# iostr730 register map
Registers are 16-bit, access not given, no defined reset value unless marked. A register's access mark holds for its fields unless they carry their own. Addresses are absolute; registers are grouped by the start of their names; [hi:lo] are bit positions; {n}, {i} and the like mark numbered series.

## GPIOPORT0
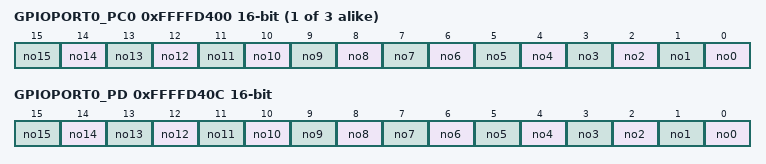
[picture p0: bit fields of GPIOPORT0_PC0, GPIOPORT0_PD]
{0xFFFFD400+4i} GPIOPORT0_PC{i} (i=0..2)
  [n] no{n} (n=0..15)
0xFFFFD40C GPIOPORT0_PD
  [n] no{n} (n=0..15)

## GPIOPORT1
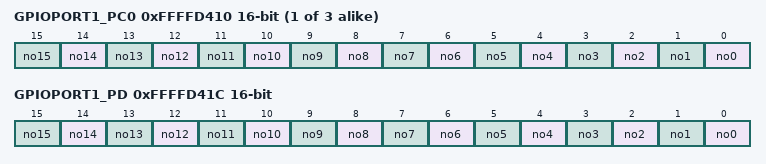
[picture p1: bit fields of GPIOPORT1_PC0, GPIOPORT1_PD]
{0xFFFFD410+4i} GPIOPORT1_PC{i} (i=0..2)
  [n] no{n} (n=0..15)
0xFFFFD41C GPIOPORT1_PD
  [n] no{n} (n=0..15)

## GPIOPORT2
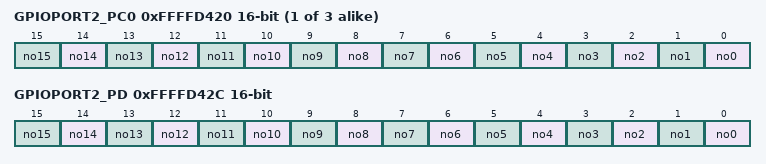
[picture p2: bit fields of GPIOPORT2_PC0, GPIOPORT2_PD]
{0xFFFFD420+4i} GPIOPORT2_PC{i} (i=0..2)
  [n] no{n} (n=0..15)
0xFFFFD42C GPIOPORT2_PD
  [n] no{n} (n=0..15)

## GPIOPORT3
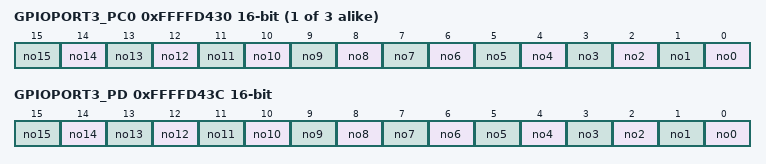
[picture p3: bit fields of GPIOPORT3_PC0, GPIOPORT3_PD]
{0xFFFFD430+4i} GPIOPORT3_PC{i} (i=0..2)
  [n] no{n} (n=0..15)
0xFFFFD43C GPIOPORT3_PD
  [n] no{n} (n=0..15)

## GPIOPORT4
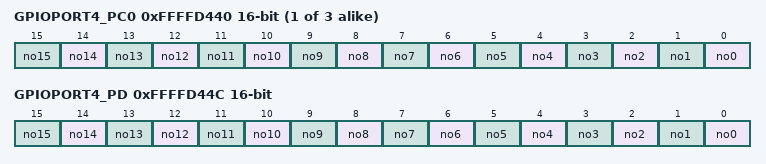
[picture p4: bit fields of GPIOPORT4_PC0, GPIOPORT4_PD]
{0xFFFFD440+4i} GPIOPORT4_PC{i} (i=0..2)
  [n] no{n} (n=0..15)
0xFFFFD44C GPIOPORT4_PD
  [n] no{n} (n=0..15)

## GPIOPORT5
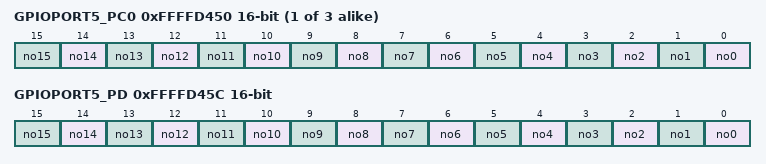
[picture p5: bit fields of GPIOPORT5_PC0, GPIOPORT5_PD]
{0xFFFFD450+4i} GPIOPORT5_PC{i} (i=0..2)
  [n] no{n} (n=0..15)
0xFFFFD45C GPIOPORT5_PD
  [n] no{n} (n=0..15)

## GPIOPORT6
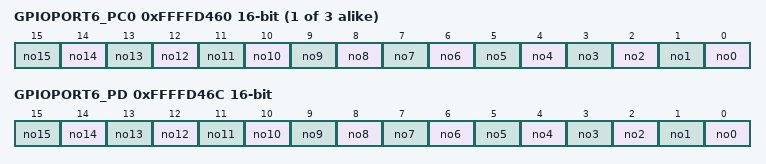
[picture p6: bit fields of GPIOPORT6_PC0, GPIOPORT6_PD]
{0xFFFFD460+4i} GPIOPORT6_PC{i} (i=0..2)
  [n] no{n} (n=0..15)
0xFFFFD46C GPIOPORT6_PD
  [n] no{n} (n=0..15)

## BSPI0
0xFFFFD800 BSPI0_RXR
0xFFFFD804 BSPI0_TXR
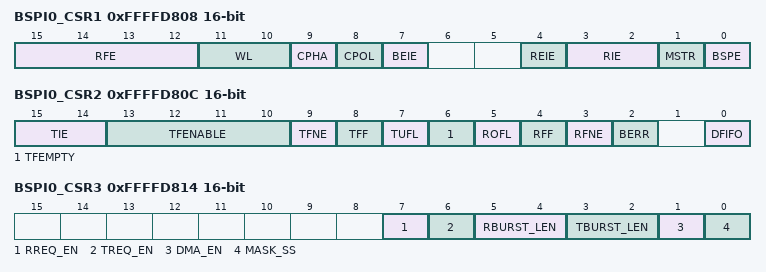
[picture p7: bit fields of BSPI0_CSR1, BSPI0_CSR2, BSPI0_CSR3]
0xFFFFD808 BSPI0_CSR1
  [15:12] RFE, [11:10] WL, [9] CPHA, [8] CPOL, [7] BEIE, [4] REIE, [3:2] RIE, [1] MSTR, [0] BSPE
0xFFFFD80C BSPI0_CSR2
  [15:14] TIE, [13:10] TFENABLE, [9] TFNE, [8] TFF, [7] TUFL, [6] TFEMPTY, [5] ROFL, [4] RFF, [3] RFNE, [2] BERR, [0] DFIFO
0xFFFFD810 BSPI0_CLK
  [7:0] DIV
0xFFFFD814 BSPI0_CSR3
  [7] RREQ_EN, [6] TREQ_EN, [5:4] RBURST_LEN, [3:2] TBURST_LEN, [1] DMA_EN, [0] MASK_SS

## BSPI1
0xFFFFDC00 BSPI1_RXR
0xFFFFDC04 BSPI1_TXR
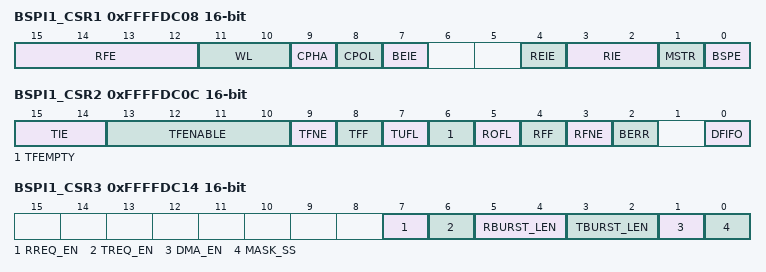
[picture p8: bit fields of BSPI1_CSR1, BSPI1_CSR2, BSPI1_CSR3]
0xFFFFDC08 BSPI1_CSR1
  [15:12] RFE, [11:10] WL, [9] CPHA, [8] CPOL, [7] BEIE, [4] REIE, [3:2] RIE, [1] MSTR, [0] BSPE
0xFFFFDC0C BSPI1_CSR2
  [15:14] TIE, [13:10] TFENABLE, [9] TFNE, [8] TFF, [7] TUFL, [6] TFEMPTY, [5] ROFL, [4] RFF, [3] RFNE, [2] BERR, [0] DFIFO
0xFFFFDC10 BSPI1_CLK
  [7:0] DIV
0xFFFFDC14 BSPI1_CSR3
  [7] RREQ_EN, [6] TREQ_EN, [5:4] RBURST_LEN, [3:2] TBURST_LEN, [1] DMA_EN, [0] MASK_SS

## BSPI2
0xFFFFE000 BSPI2_RXR
0xFFFFE004 BSPI2_TXR
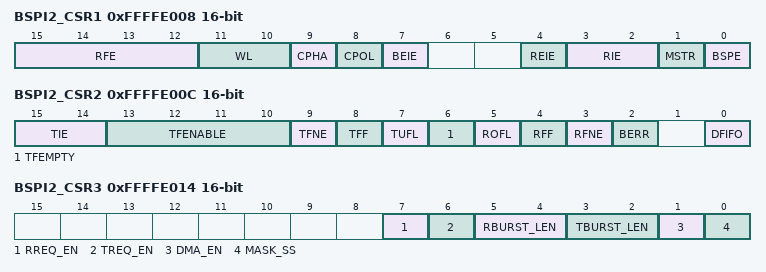
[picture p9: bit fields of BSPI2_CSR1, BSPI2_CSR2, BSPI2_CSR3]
0xFFFFE008 BSPI2_CSR1
  [15:12] RFE, [11:10] WL, [9] CPHA, [8] CPOL, [7] BEIE, [4] REIE, [3:2] RIE, [1] MSTR, [0] BSPE
0xFFFFE00C BSPI2_CSR2
  [15:14] TIE, [13:10] TFENABLE, [9] TFNE, [8] TFF, [7] TUFL, [6] TFEMPTY, [5] ROFL, [4] RFF, [3] RFNE, [2] BERR, [0] DFIFO
0xFFFFE010 BSPI2_CLK
  [7:0] DIV
0xFFFFE014 BSPI2_CSR3
  [7] RREQ_EN, [6] TREQ_EN, [5:4] RBURST_LEN, [3:2] TBURST_LEN, [1] DMA_EN, [0] MASK_SS

## TIM2
0xFFFFE400 TIM2_ICAR
0xFFFFE404 TIM2_ICBR
0xFFFFE408 TIM2_OCAR
0xFFFFE40C TIM2_OCBR
0xFFFFE410 TIM2_CNTR
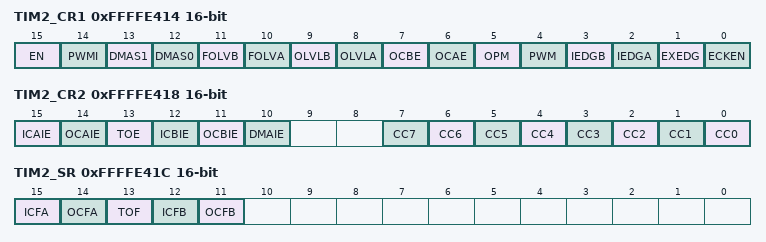
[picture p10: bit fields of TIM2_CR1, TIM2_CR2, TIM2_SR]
0xFFFFE414 TIM2_CR1
  [15] EN, [14] PWMI, [13] DMAS1, [12] DMAS0, [11] FOLVB, [10] FOLVA, [9] OLVLB, [8] OLVLA, [7] OCBE, [6] OCAE, [5] OPM, [4] PWM, [3] IEDGB, [2] IEDGA, [1] EXEDG, [0] ECKEN
0xFFFFE418 TIM2_CR2
  [15] ICAIE, [14] OCAIE, [13] TOE, [12] ICBIE, [11] OCBIE, [10] DMAIE, [n] CC{n} (n=0..7)
0xFFFFE41C TIM2_SR
  [15] ICFA, [14] OCFA, [13] TOF, [12] ICFB, [11] OCFB

## TIM3
0xFFFFE800 TIM3_ICAR
0xFFFFE804 TIM3_ICBR
0xFFFFE808 TIM3_OCAR
0xFFFFE80C TIM3_OCBR
0xFFFFE810 TIM3_CNTR
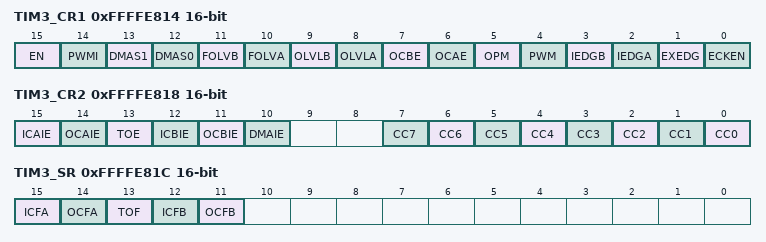
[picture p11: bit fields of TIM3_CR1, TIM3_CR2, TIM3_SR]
0xFFFFE814 TIM3_CR1
  [15] EN, [14] PWMI, [13] DMAS1, [12] DMAS0, [11] FOLVB, [10] FOLVA, [9] OLVLB, [8] OLVLA, [7] OCBE, [6] OCAE, [5] OPM, [4] PWM, [3] IEDGB, [2] IEDGA, [1] EXEDG, [0] ECKEN
0xFFFFE818 TIM3_CR2
  [15] ICAIE, [14] OCAIE, [13] TOE, [12] ICBIE, [11] OCBIE, [10] DMAIE, [n] CC{n} (n=0..7)
0xFFFFE81C TIM3_SR
  [15] ICFA, [14] OCFA, [13] TOF, [12] ICFB, [11] OCFB

## TIM4
0xFFFFEC00 TIM4_ICAR
0xFFFFEC04 TIM4_ICBR
0xFFFFEC08 TIM4_OCAR
0xFFFFEC0C TIM4_OCBR
0xFFFFEC10 TIM4_CNTR
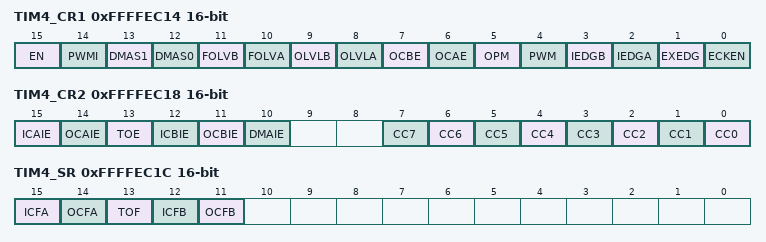
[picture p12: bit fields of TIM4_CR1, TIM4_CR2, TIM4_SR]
0xFFFFEC14 TIM4_CR1
  [15] EN, [14] PWMI, [13] DMAS1, [12] DMAS0, [11] FOLVB, [10] FOLVA, [9] OLVLB, [8] OLVLA, [7] OCBE, [6] OCAE, [5] OPM, [4] PWM, [3] IEDGB, [2] IEDGA, [1] EXEDG, [0] ECKEN
0xFFFFEC18 TIM4_CR2
  [15] ICAIE, [14] OCAIE, [13] TOE, [12] ICBIE, [11] OCBIE, [10] DMAIE, [n] CC{n} (n=0..7)
0xFFFFEC1C TIM4_SR
  [15] ICFA, [14] OCFA, [13] TOF, [12] ICFB, [11] OCFB
